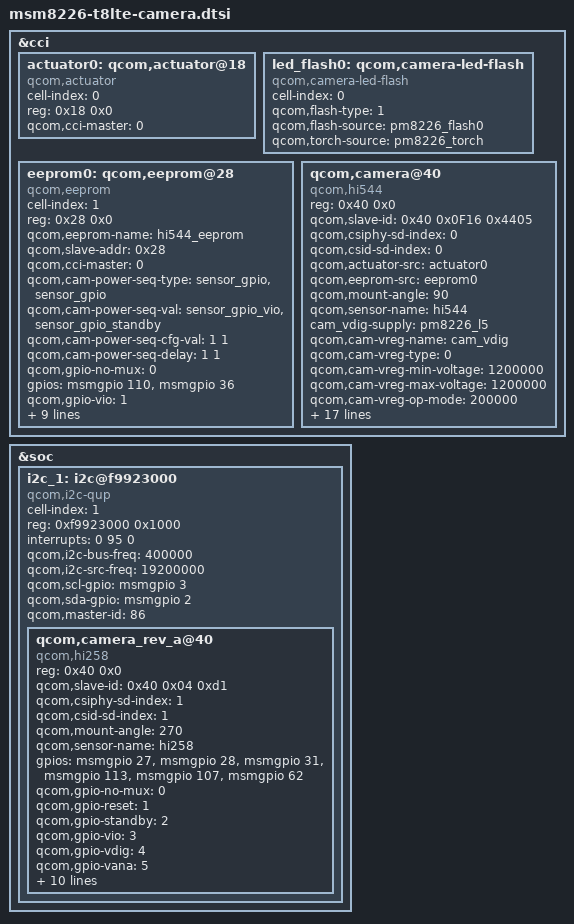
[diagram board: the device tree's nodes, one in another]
/*
 * Copyright (c) 2013, The Linux Foundation. All rights reserved.
 *
 * This program is free software; you can redistribute it and/or modify
 * it under the terms of the GNU General Public License version 2 and
 * only version 2 as published by the Free Software Foundation.
 *
 * This program is distributed in the hope that it will be useful,
 * but WITHOUT ANY WARRANTY; without even the implied warranty of
 * MERCHANTABILITY or FITNESS FOR A PARTICULAR PURPOSE.  See the
 * GNU General Public License for more details.
 */

&cci {
	actuator0: qcom,actuator@18 {
		cell-index = <0>;	//Use Af_main_0 of dw9716 with HI544
		reg = <0x18 0x0>;
		compatible = "qcom,actuator";
		qcom,cci-master = <0>;
	};

	led_flash0: qcom,camera-led-flash {
		cell-index = <0>;
		compatible = "qcom,camera-led-flash";
		qcom,flash-type = <1>;
		qcom,flash-source = <&pm8226_flash0>;
        qcom,torch-source = <&pm8226_torch>;
	};

	eeprom0: qcom,eeprom@28 { //EEPROM READ
		cell-index = <1>;
		reg = <0x28 0x0>;
		qcom,eeprom-name = "hi544_eeprom";
		compatible = "qcom,eeprom";
		qcom,slave-addr = <0x28>;
		qcom,cci-master = <0>;

		qcom,cam-power-seq-type = "sensor_gpio","sensor_gpio";
		qcom,cam-power-seq-val = "sensor_gpio_vio","sensor_gpio_standby";
		qcom,cam-power-seq-cfg-val = <1 1>;
		qcom,cam-power-seq-delay = <1 1>;
		qcom,gpio-no-mux = <0>;
		gpios = <&msmgpio 110 0>,	//1.8V IOVDD
			<&msmgpio 36 0>;		//2.8V VCM
		qcom,gpio-vio = <1>;
		qcom,gpio-standby = <0>;		//CAM_STANDBY
		qcom,gpio-req-tbl-num = <0 1>;
		qcom,gpio-req-tbl-flags = <0 0>;
		qcom,gpio-req-tbl-label = "MAIN_VIO_EN","CAM_STANDBY";

		qcom,num-blocks = <1>;
		qcom,page0 = <0 0x0 1 0x0 1 20>; // valid size, addr, addr_t, data, data_t, delay
		qcom,poll0 = <0 0x0 1 0x0 1 20>;
		qcom,mem0  = <0x382 0x0000 2 0 1 0>; // EEPROM READ
	};

	qcom,camera@40 {
		compatible           = "qcom,hi544";
		reg                  = <0x40 0x0>;
		qcom,slave-id        = <0x40 0x0F16 0x4405>;
		qcom,csiphy-sd-index = <0>;
		qcom,csid-sd-index   = <0>;
		qcom,actuator-src    = <&actuator0>;
		//qcom,led-flash-src   = <&led_flash0>;
		qcom,eeprom-src      = <&eeprom0>;
		qcom,mount-angle     = <90>;
		qcom,sensor-name     = "hi544";

		cam_vdig-supply = <&pm8226_l5>;		//CAM_DVDD_1V8_1V2
		qcom,cam-vreg-name = "cam_vdig";
		qcom,cam-vreg-type = <0>;
		qcom,cam-vreg-min-voltage = <1200000>;
		qcom,cam-vreg-max-voltage = <1200000>;
		qcom,cam-vreg-op-mode = <200000>;

		gpios = <&msmgpio 26 0>,     //MAIN_CAM0_MCLK
			<&msmgpio 114 0>,    //MAIN_CAM0_RESET_N --> StandBy
			<&msmgpio 36 0>,     //MAIN_CAM0_VCM_PWDN
			<&msmgpio 62 0>,     //CAM_AVDD_2.8V,  LDO1_EN=GPIO 62
			<&msmgpio 110 0>;    //CAM_IOVDD_1.8V, LDO2_EN=GPIO 110

		qcom,gpio-no-mux  = <0>;
		qcom,gpio-standby = <1>; //gpio-reset
		qcom,gpio-af-pwdm = <2>;
		qcom,gpio-vana    = <3>;
		qcom,gpio-vio     = <4>;
		qcom,gpio-req-tbl-num   = <0 1 2 3 4>;
		qcom,gpio-req-tbl-flags = <1 0 0 0 0>;
		qcom,gpio-req-tbl-label	= "CAMIF_MCLK",
		                          "CAM_STANDBY",
		                          "MAIN_AF_PWDN",
		                          "MAIN_VANA_EN",
		                          "MAIN_VIO_EN";

		qcom,csi-lane-assign = <0x4320>;
		qcom,csi-lane-mask = <0x07>;
		qcom,sensor-position = <0>;
		qcom,sensor-mode = <0>;
		qcom,cci-master = <0>;
		//revision = "...rev_a";
		status = "okay";
	};
};

&soc {
	/*  LGE_CHANGE_S, Camerato use QUP I2C port.20141226.sujeong.kwon@lge.com*/
	i2c_1: i2c@f9923000 {   /* BLSP-1 QUP1 - Using fuel gauge */
		cell-index = <1>;
		compatible = "qcom,i2c-qup";
		reg = <0xf9923000 0x1000>;
		#address-cells = <1>;
		#size-cells = <0>;
		reg-names = "qup_phys_addr";
		interrupts = <0 95 0>;
		interrupt-names = "qup_err_intr";
		qcom,i2c-bus-freq = <400000>;   //400KHz
		qcom,i2c-src-freq = <19200000>;
		qcom,scl-gpio = <&msmgpio 3 0>;
		qcom,sda-gpio = <&msmgpio 2 0>;
		qcom,master-id = <86>;
		status = "ok";
	};
	/*  LGE_CHANGE_E, Camerato use QUP I2C port.20141226.sujeong.kwon@lge.com*/
};

&i2c_1 {
	//i2c@f9923000{ /* BLSP1 QUP1 */
	    qcom,camera_rev_a@40 {
	            compatible = "qcom,hi258";
	            reg = <0x40 0x0>;
	            qcom,slave-id = <0x40 0x04 0xd1>;
	            qcom,csiphy-sd-index = <1>;
	            qcom,csid-sd-index = <1>;
	            qcom,mount-angle = <270>;
	            qcom,sensor-name = "hi258";

	            gpios = <&msmgpio 27 0>,			//VT_CAM_MCLK,
	                    <&msmgpio 28 0>,            //VT_CAM_RESET_N,
	                    <&msmgpio 31 0>,            //VT_CAM_PWDN,
	                    <&msmgpio 113 0>,		//VT_CAM_IOVDD_1V8, LDO3_EN=GPIO 113
		    	    	<&msmgpio 107 0>,		//VT_CAM_DVDD_1V8, LDO6_EN=GPIO 107
	    		    	<&msmgpio 62 0>;		//CAM_AVDD_2.8V,  LDO1_EN=GPIO 62

		    qcom,gpio-no-mux = <0>;
	            qcom,gpio-reset = <1>;
	            qcom,gpio-standby = <2>;
	            qcom,gpio-vio = <3>;
				qcom,gpio-vdig = <4>;
				qcom,gpio-vana = <5>;
				qcom,gpio-req-tbl-num = <0 1 2 3 4 5>;
				qcom,gpio-req-tbl-flags = <1 0 0 0 0 0>;
				qcom,gpio-req-tbl-label = "VT_CAM_MCLK",
							"VT_CAM_RESET",
							"VT_CAM_PWDN",
							"VT_CAM_IOVDD_1V8",
							"VT_CAM_DVDD_1V8",
							"VT_CAM_AVDD_2V8";

	            qcom,csi-lane-assign = <0x4320>;
	            qcom,csi-lane-mask = <0x3>;
	            qcom,sensor-position = <1>;
	            qcom,sensor-mode = <1>;
	            //qcom,cci-master = <0>;
	            qcom,sensor-type= <1>;
	            //revision = "...rev_a";
	            status = "okay";
	    };
   //};
};

